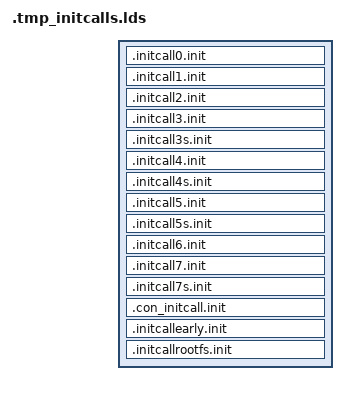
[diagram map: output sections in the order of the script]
SECTIONS {
	.initcall0.init : {
		*(.initcall0.init..kmod_core__443_830_bpf_jit_charge_init) ;
		*(.initcall0.init..kmod_memcontrol__764_1551_memory_stats_init) ;
		*(.initcall0.init..kmod_min_addr__299_53_init_mmap_min_addr) ;
		*(.initcall0.init..kmod_pci__471_6608_pci_realloc_setup_params) ;
		*(.initcall0.init..kmod_net_namespace__604_1140_net_ns_init) ;
	}
	.initcall1.init : {
		*(.initcall1.init..kmod_fpsimd__313_1449_fpsimd_init) ;
		*(.initcall1.init..kmod_process__417_747_tagged_addr_init) ;
		*(.initcall1.init..kmod_cpufeature__339_3096_enable_mrs_emulation) ;
		*(.initcall1.init..kmod_armv8_deprecated__334_647_armv8_deprecated_init) ;
		*(.initcall1.init..kmod_kaslr__313_198_kaslr_init) ;
		*(.initcall1.init..kmod_mmu__406_619_map_entry_trampoline) ;
		*(.initcall1.init..kmod_cpu__562_1806_alloc_frozen_cpus) ;
		*(.initcall1.init..kmod_cpu__564_1853_cpu_hotplug_pm_sync_init) ;
		*(.initcall1.init..kmod_workqueue__530_5652_wq_sysfs_init) ;
		*(.initcall1.init..kmod_ksysfs__308_269_ksysfs_init) ;
		*(.initcall1.init..kmod_cpufreq_schedutil__706_907_schedutil_gov_init) ;
		*(.initcall1.init..kmod_main__390_959_pm_init) ;
		*(.initcall1.init..kmod_update__437_238_rcu_set_runtime_mode) ;
		*(.initcall1.init..kmod_coherent__314_402_dma_init_reserved_memory) ;
		*(.initcall1.init..kmod_jiffies__297_86_init_jiffies_clocksource) ;
		*(.initcall1.init..kmod_futex__381_4044_futex_init) ;
		*(.initcall1.init..kmod_cgroup__737_5840_cgroup_wq_init) ;
		*(.initcall1.init..kmod_cgroup_v1__381_1253_cgroup1_wq_init) ;
		*(.initcall1.init..kmod_trace_events_synth__346_2079_trace_events_synth_init_early) ;
		*(.initcall1.init..kmod_trace_kprobe__365_1917_init_kprobe_trace_early) ;
		*(.initcall1.init..kmod_cpu_pm__272_213_cpu_pm_init) ;
		*(.initcall1.init..kmod_memcontrol__964_7530_mem_cgroup_swap_init) ;
		*(.initcall1.init..kmod_cma__437_161_cma_init_reserved_areas) ;
		*(.initcall1.init..kmod_fsnotify__331_572_fsnotify_init) ;
		*(.initcall1.init..kmod_locks__467_3023_filelock_init) ;
		*(.initcall1.init..kmod_binfmt_misc__342_832_init_misc_binfmt) ;
		*(.initcall1.init..kmod_binfmt_script__266_156_init_script_binfmt) ;
		*(.initcall1.init..kmod_binfmt_elf__346_2309_init_elf_binfmt) ;
		*(.initcall1.init..kmod_compat_binfmt_elf__346_2309_init_compat_elf_binfmt) ;
		*(.initcall1.init..kmod_configfs__329_179_configfs_init) ;
		*(.initcall1.init..kmod_debugfs__334_847_debugfs_init) ;
		*(.initcall1.init..kmod_tracefs__314_550_tracefs_init) ;
		*(.initcall1.init..kmod_inode__326_350_securityfs_init) ;
		*(.initcall1.init..kmod_random32__421_489_prandom_init_early) ;
		*(.initcall1.init..kmod_core__397_2305_pinctrl_init) ;
		*(.initcall1.init..kmod_gpiolib__447_4423_gpiolib_dev_init) ;
		*(.initcall1.init..kmod_crg_hi3516cv300__297_309_hi3516cv300_crg_init) ;
		*(.initcall1.init..kmod_clk_hi3519__297_194_hi3519_clk_init) ;
		*(.initcall1.init..kmod_clk_hi3660__261_637_hi3660_clk_init) ;
		*(.initcall1.init..kmod_clk_hi3670__261_1016_hi3670_clk_init) ;
		*(.initcall1.init..kmod_crg_hi3798cv200__297_392_hi3798cv200_crg_init) ;
		*(.initcall1.init..kmod_virtio__326_465_virtio_init) ;
		*(.initcall1.init..kmod_core__528_5860_regulator_init) ;
		*(.initcall1.init..kmod_iommu__427_2738_iommu_init) ;
		*(.initcall1.init..kmod_component__264_124_component_debug_init) ;
		*(.initcall1.init..kmod_domain__453_2956_genpd_bus_init) ;
		*(.initcall1.init..kmod_soc__237_192_soc_bus_register) ;
		*(.initcall1.init..kmod_arch_topology__346_296_register_cpufreq_notifier) ;
		*(.initcall1.init..kmod_debugfs__266_249_opp_debug_init) ;
		*(.initcall1.init..kmod_cpufreq__553_2887_cpufreq_core_init) ;
		*(.initcall1.init..kmod_cpufreq_performance__283_44_cpufreq_gov_performance_init) ;
		*(.initcall1.init..kmod_cpufreq_powersave__283_38_cpufreq_gov_powersave_init) ;
		*(.initcall1.init..kmod_cpufreq_conservative__287_340_CPU_FREQ_GOV_CONSERVATIVE_init) ;
		*(.initcall1.init..kmod_cpuidle__478_771_cpuidle_init) ;
		*(.initcall1.init..kmod_capsule__319_303_capsule_reboot_register) ;
		*(.initcall1.init..kmod_arm_runtime__316_178_arm_dmi_init) ;
		*(.initcall1.init..kmod_hi3660_mailbox__299_291_hi3660_mbox_init) ;
		*(.initcall1.init..kmod_hi6220_mailbox__308_366_hi6220_mbox_init) ;
		*(.initcall1.init..kmod_socket__666_3080_sock_init) ;
		*(.initcall1.init..kmod_sock__847_3388_net_inuse_init) ;
		*(.initcall1.init..kmod_net_namespace__573_393_net_defaults_init) ;
		*(.initcall1.init..kmod_flow_dissector__679_1808_init_default_flow_dissectors) ;
		*(.initcall1.init..kmod_af_netlink__671_2903_netlink_proto_init) ;
		*(.initcall1.init..kmod_genetlink__565_1411_genl_init) ;
	}
	.initcall2.init : {
		*(.initcall2.init..kmod_debug_monitors__318_139_debug_monitors_init) ;
		*(.initcall2.init..kmod_irqdesc__274_331_irq_sysfs_init) ;
		*(.initcall2.init..kmod_pool__316_225_dma_atomic_pool_init) ;
		*(.initcall2.init..kmod_audit__582_1690_audit_init) ;
		*(.initcall2.init..kmod_tracepoint__271_140_release_early_probes) ;
		*(.initcall2.init..kmod_backing_dev__474_231_bdi_class_init) ;
		*(.initcall2.init..kmod_mm_init__334_207_mm_sysfs_init) ;
		*(.initcall2.init..kmod_page_alloc__678_8141_init_per_zone_wmark_min) ;
		*(.initcall2.init..kmod_ramoops__318_975_ramoops_init) ;
		*(.initcall2.init..kmod_mpi__307_64_mpi_init) ;
		*(.initcall2.init..kmod_kobject_uevent__554_814_kobject_uevent_init) ;
		*(.initcall2.init..kmod_probe__320_108_pcibus_class_init) ;
		*(.initcall2.init..kmod_pci_driver__427_1659_pci_driver_init) ;
		*(.initcall2.init..kmod_backlight__343_770_backlight_class_init) ;
		*(.initcall2.init..kmod_bus__392_230_amba_init) ;
		*(.initcall2.init..kmod_hi6220_reset__303_221_hi6220_reset_init) ;
		*(.initcall2.init..kmod_tty_io__379_3515_tty_class_init) ;
		*(.initcall2.init..kmod_serdev__309_896_serdev_init) ;
		*(.initcall2.init..kmod_iommu_sysfs__304_47_iommu_dev_init) ;
		*(.initcall2.init..kmod_drm_mipi_dsi__362_1210_mipi_dsi_bus_init) ;
		*(.initcall2.init..kmod_core__430_603_devlink_class_init) ;
		*(.initcall2.init..kmod_swnode__276_973_software_node_init) ;
		*(.initcall2.init..kmod_wakeup__516_1238_wakeup_sources_debugfs_init) ;
		*(.initcall2.init..kmod_wakeup_stats__233_217_wakeup_sources_sysfs_init) ;
		*(.initcall2.init..kmod_regmap__439_3298_regmap_initcall) ;
		*(.initcall2.init..kmod_sram__268_429_sram_init) ;
		*(.initcall2.init..kmod_syscon__269_312_syscon_init) ;
		*(.initcall2.init..kmod_spi__521_4255_spi_init) ;
		*(.initcall2.init..kmod_spmi__368_591_spmi_init) ;
		*(.initcall2.init..kmod_i2c_core__404_1933_i2c_init) ;
		*(.initcall2.init..kmod_thermal_sys__487_1694_thermal_init) ;
		*(.initcall2.init..kmod_menu__262_574_init_menu) ;
		*(.initcall2.init..kmod_teo__260_494_teo_governor_init) ;
		*(.initcall2.init..kmod_rpmsg_core__301_635_rpmsg_init) ;
		*(.initcall2.init..kmod_rpmsg_char__345_572_rpmsg_char_init) ;
	}
	.initcall3.init : {
		*(.initcall3.init..kmod_setup__324_290_reserve_memblock_reserved_regions) ;
		*(.initcall3.init..kmod_vdso__318_381_aarch32_alloc_vdso_pages) ;
		*(.initcall3.init..kmod_vdso__320_486_vdso_init) ;
		*(.initcall3.init..kmod_hw_breakpoint__322_1018_arch_hw_breakpoint_init) ;
		*(.initcall3.init..kmod_context__324_399_asids_update_limit) ;
		*(.initcall3.init..kmod_kcmp__330_256_kcmp_cookies_init) ;
		*(.initcall3.init..kmod_cryptomgr__396_288_cryptomgr_init) ;
		*(.initcall3.init..kmod_dmaengine__321_293_dma_channel_table_init) ;
		*(.initcall3.init..kmod_dmaengine__393_1659_dma_bus_init) ;
		*(.initcall3.init..kmod_reset_hi3660__298_118_hi3660_reset_init) ;
		*(.initcall3.init..kmod_amba_pl011__414_2860_pl011_init) ;
		*(.initcall3.init..kmod_dma_iommu__357_1345_iommu_dma_init) ;
	}
	.initcall3s.init : {
		*(.initcall3s.init..kmod_platform__389_545_of_platform_default_populate_init) ;
	}
	.initcall4.init : {
		*(.initcall4.init..kmod_setup__326_421_topology_init) ;
		*(.initcall4.init..kmod_mte__388_486_register_mte_tcf_preferred_sysctl) ;
		*(.initcall4.init..kmod_user__245_235_uid_cache_init) ;
		*(.initcall4.init..kmod_params__366_958_param_sysfs_init) ;
		*(.initcall4.init..kmod_ucount__229_242_user_namespace_sysctl_init) ;
		*(.initcall4.init..kmod_stats__573_128_proc_schedstat_init) ;
		*(.initcall4.init..kmod_poweroff__165_45_pm_sysrq_init) ;
		*(.initcall4.init..kmod_profile__324_565_create_proc_profile) ;
		*(.initcall4.init..kmod_namespace__305_478_time_ns_init) ;
		*(.initcall4.init..kmod_cgroup__745_6662_cgroup_sysfs_init) ;
		*(.initcall4.init..kmod_namespace__320_157_cgroup_namespaces_init) ;
		*(.initcall4.init..kmod_hung_task__501_321_hung_task_init) ;
		*(.initcall4.init..kmod_bpf_trace__523_2183_send_signal_irq_work_init) ;
		*(.initcall4.init..kmod_devmap__518_876_dev_map_init) ;
		*(.initcall4.init..kmod_cpumap__505_768_cpu_map_init) ;
		*(.initcall4.init..kmod_net_namespace__436_566_netns_bpf_init) ;
		*(.initcall4.init..kmod_stackmap__436_874_stack_map_init) ;
		*(.initcall4.init..kmod_oom_kill__525_720_oom_init) ;
		*(.initcall4.init..kmod_backing_dev__476_248_default_bdi_init) ;
		*(.initcall4.init..kmod_backing_dev__504_692_cgwb_init) ;
		*(.initcall4.init..kmod_percpu__456_3183_percpu_enable_async) ;
		*(.initcall4.init..kmod_compaction__499_3005_kcompactd_init) ;
		*(.initcall4.init..kmod_mmap__561_3873_init_user_reserve) ;
		*(.initcall4.init..kmod_mmap__565_3894_init_admin_reserve) ;
		*(.initcall4.init..kmod_mmap__567_3964_init_reserve_notifier) ;
		*(.initcall4.init..kmod_swap_state__403_957_swap_init_sysfs) ;
		*(.initcall4.init..kmod_swapfile__477_3862_swapfile_init) ;
		*(.initcall4.init..kmod_huge_memory__397_446_hugepage_init) ;
		*(.initcall4.init..kmod_memcontrol__955_7174_mem_cgroup_init) ;
		*(.initcall4.init..kmod_cma_sysfs__268_118_cma_sysfs_init) ;
		*(.initcall4.init..kmod_io_wq__600_1242_io_wq_init) ;
		*(.initcall4.init..kmod_seqiv__329_183_seqiv_module_init) ;
		*(.initcall4.init..kmod_echainiv__329_160_echainiv_module_init) ;
		*(.initcall4.init..kmod_rsa_generic__314_281_rsa_init) ;
		*(.initcall4.init..kmod_cmac__277_311_crypto_cmac_module_init) ;
		*(.initcall4.init..kmod_hmac__325_254_hmac_module_init) ;
		*(.initcall4.init..kmod_xcbc__277_270_crypto_xcbc_module_init) ;
		*(.initcall4.init..kmod_crypto_null__331_221_crypto_null_mod_init) ;
		*(.initcall4.init..kmod_md5__278_245_md5_mod_init) ;
		*(.initcall4.init..kmod_sha1_generic__320_89_sha1_generic_mod_init) ;
		*(.initcall4.init..kmod_sha256_generic__321_113_sha256_generic_mod_init) ;
		*(.initcall4.init..kmod_sha512_generic__321_221_sha512_generic_mod_init) ;
		*(.initcall4.init..kmod_blake2b_generic__278_174_blake2b_mod_init) ;
		*(.initcall4.init..kmod_ecb__275_99_crypto_ecb_module_init) ;
		*(.initcall4.init..kmod_cbc__275_218_crypto_cbc_module_init) ;
		*(.initcall4.init..kmod_cts__323_405_crypto_cts_module_init) ;
		*(.initcall4.init..kmod_xts__323_462_xts_module_init) ;
		*(.initcall4.init..kmod_ctr__277_355_crypto_ctr_module_init) ;
		*(.initcall4.init..kmod_adiantum__340_613_adiantum_module_init) ;
		*(.initcall4.init..kmod_nhpoly1305__292_248_nhpoly1305_mod_init) ;
		*(.initcall4.init..kmod_gcm__341_1159_crypto_gcm_module_init) ;
		*(.initcall4.init..kmod_ccm__343_949_crypto_ccm_module_init) ;
		*(.initcall4.init..kmod_chacha20poly1305__341_671_chacha20poly1305_module_init) ;
		*(.initcall4.init..kmod_des_generic__273_125_des_generic_mod_init) ;
		*(.initcall4.init..kmod_aes_generic__270_1314_aes_init) ;
		*(.initcall4.init..kmod_chacha_generic__275_128_chacha_generic_mod_init) ;
		*(.initcall4.init..kmod_poly1305_generic__279_142_poly1305_mod_init) ;
		*(.initcall4.init..kmod_deflate__313_334_deflate_mod_init) ;
		*(.initcall4.init..kmod_crc32c_generic__277_161_crc32c_mod_init) ;
		*(.initcall4.init..kmod_crc32_generic__277_147_crc32_mod_init) ;
		*(.initcall4.init..kmod_authenc__420_464_crypto_authenc_module_init) ;
		*(.initcall4.init..kmod_authencesn__418_479_crypto_authenc_esn_module_init) ;
		*(.initcall4.init..kmod_lz4__269_155_lz4_mod_init) ;
		*(.initcall4.init..kmod_ansi_cprng__276_470_prng_mod_init) ;
		*(.initcall4.init..kmod_drbg__338_2146_drbg_init) ;
		*(.initcall4.init..kmod_ghash_generic__280_178_ghash_mod_init) ;
		*(.initcall4.init..kmod_zstd__313_253_zstd_mod_init) ;
		*(.initcall4.init..kmod_essiv__340_641_essiv_module_init) ;
		*(.initcall4.init..kmod_ecdh_generic__313_167_ecdh_init) ;
		*(.initcall4.init..kmod_bio__499_1686_init_bio) ;
		*(.initcall4.init..kmod_blk_settings__463_887_blk_settings_init) ;
		*(.initcall4.init..kmod_blk_ioc__367_422_blk_ioc_init) ;
		*(.initcall4.init..kmod_blk_mq__542_4036_blk_mq_init) ;
		*(.initcall4.init..kmod_genhd__400_1235_genhd_device_init) ;
		*(.initcall4.init..kmod_blk_cgroup__447_1943_blkcg_init) ;
		*(.initcall4.init..kmod_blk_crypto__352_79_bio_crypt_ctx_init) ;
		*(.initcall4.init..kmod_gpiolib__452_4550_gpiolib_debugfs_init) ;
		*(.initcall4.init..kmod_core__364_1347_pwm_debugfs_init) ;
		*(.initcall4.init..kmod_sysfs__233_554_pwm_sysfs_init) ;
		*(.initcall4.init..kmod_slot__329_379_pci_slot_init) ;
		*(.initcall4.init..kmod_clk_hi6220_stub__266_272_hi6220_stub_clk_init) ;
		*(.initcall4.init..kmod_clk_hi3660_stub__299_178_hi3660_stub_clk_init) ;
		*(.initcall4.init..kmod_fixed__377_290_regulator_fixed_voltage_init) ;
		*(.initcall4.init..kmod_misc__286_291_misc_init) ;
		*(.initcall4.init..kmod_iommu__335_152_iommu_subsys_init) ;
		*(.initcall4.init..kmod_arch_topology__341_115_register_cpu_capacity_sysctl) ;
		*(.initcall4.init..kmod_act8945a__302_82_act8945a_i2c_init) ;
		*(.initcall4.init..kmod_libnvdimm__399_616_libnvdimm_init) ;
		*(.initcall4.init..kmod_dax__386_763_dax_core_init) ;
		*(.initcall4.init..kmod_dma_buf__352_1551_dma_buf_init) ;
		*(.initcall4.init..kmod_dma_heap__348_463_dma_heap_init) ;
		*(.initcall4.init..kmod_scsi_mod__422_804_init_scsi) ;
		*(.initcall4.init..kmod_libphy__512_3061_phy_init) ;
		*(.initcall4.init..kmod_usb_common__398_412_usb_common_init) ;
		*(.initcall4.init..kmod_usbcore__424_1075_usb_init) ;
		*(.initcall4.init..kmod_udc_core__462_1772_usb_udc_init) ;
		*(.initcall4.init..kmod_typec__370_2132_typec_init) ;
		*(.initcall4.init..kmod_roles__285_387_usb_roles_init) ;
		*(.initcall4.init..kmod_serio__326_1052_serio_init) ;
		*(.initcall4.init..kmod_input_core__407_2528_input_init) ;
		*(.initcall4.init..kmod_rtc_core__274_478_rtc_init) ;
		*(.initcall4.init..kmod_i3c__330_2705_i3c_init) ;
		*(.initcall4.init..kmod_mc__312_323_media_devnode_init) ;
		*(.initcall4.init..kmod_videodev__335_1127_videodev_init) ;
		*(.initcall4.init..kmod_rc_core__337_2090_rc_core_init) ;
		*(.initcall4.init..kmod_cec__323_448_cec_devnode_init) ;
		*(.initcall4.init..kmod_power_supply__303_1458_power_supply_class_init) ;
		*(.initcall4.init..kmod_edac_core__314_163_edac_init) ;
		*(.initcall4.init..kmod_cpuidle_psci_domain__239_316_psci_idle_init_domains) ;
		*(.initcall4.init..kmod_mmc_core__434_2399_mmc_init) ;
		*(.initcall4.init..kmod_led_class__278_540_leds_init) ;
		*(.initcall4.init..kmod_scmi_module__426_1634_scmi_driver_init) ;
		*(.initcall4.init..kmod_efi__314_436_efisubsys_init) ;
		*(.initcall4.init..kmod_efi_init__313_367_register_gop_device) ;
		*(.initcall4.init..kmod_remoteproc__392_2479_remoteproc_init) ;
		*(.initcall4.init..kmod_devfreq__395_1882_devfreq_init) ;
		*(.initcall4.init..kmod_devfreq_event__251_482_devfreq_event_init) ;
		*(.initcall4.init..kmod_governor_simpleondemand__267_128_devfreq_simple_ondemand_init) ;
		*(.initcall4.init..kmod_governor_performance__267_48_devfreq_performance_init) ;
		*(.initcall4.init..kmod_governor_powersave__267_48_devfreq_powersave_init) ;
		*(.initcall4.init..kmod_governor_userspace__270_143_devfreq_userspace_init) ;
		*(.initcall4.init..kmod_governor_passive__268_192_devfreq_passive_init) ;
		*(.initcall4.init..kmod_industrialio__319_1882_iio_init) ;
		*(.initcall4.init..kmod_arm_pmu__344_1009_arm_pmu_hp_init) ;
		*(.initcall4.init..kmod_ras__351_38_ras_init) ;
		*(.initcall4.init..kmod_nvmem_core__318_1667_nvmem_init) ;
		*(.initcall4.init..kmod_soundcore__272_65_init_soundcore) ;
		*(.initcall4.init..kmod_snd__287_410_alsa_sound_init) ;
		*(.initcall4.init..kmod_sock__854_3688_proto_init) ;
		*(.initcall4.init..kmod_dev__1261_11336_net_dev_init) ;
		*(.initcall4.init..kmod_neighbour__693_3743_neigh_init) ;
		*(.initcall4.init..kmod_fib_notifier__404_199_fib_notifier_init) ;
		*(.initcall4.init..kmod_fib_rules__678_1298_fib_rules_init) ;
		*(.initcall4.init..kmod_netprio_cgroup__570_302_init_cgroup_netprio) ;
		*(.initcall4.init..kmod_sch_api__610_2304_pktsched_init) ;
		*(.initcall4.init..kmod_cls_api__734_3927_tc_filter_init) ;
		*(.initcall4.init..kmod_act_api__585_1690_tc_action_init) ;
		*(.initcall4.init..kmod_ethtool_nl__553_949_ethnl_init) ;
		*(.initcall4.init..kmod_nexthop__669_2025_nexthop_init) ;
		*(.initcall4.init..kmod_bluetooth__582_797_bt_init) ;
		*(.initcall4.init..kmod_wext_core__398_408_wireless_nlevent_init) ;
		*(.initcall4.init..kmod_rfkill__328_1370_rfkill_init) ;
		*(.initcall4.init..kmod_ieee802154__403_374_wpan_phy_class_init) ;
		*(.initcall4.init..kmod_mac802154__580_237_ieee802154_init) ;
		*(.initcall4.init..kmod_nfc__583_1227_nfc_init) ;
	}
	.initcall4s.init : {
		*(.initcall4s.init..kmod_cpufeature__337_2982_init_32bit_el0_mask) ;
		*(.initcall4s.init..kmod_watchdog__278_438_watchdog_init) ;
	}
	.initcall5.init : {
		*(.initcall5.init..kmod_debug_monitors__316_63_create_debug_debugfs_entry) ;
		*(.initcall5.init..kmod_energy_model__264_101_em_debug_init) ;
		*(.initcall5.init..kmod_clocksource__310_928_clocksource_done_booting) ;
		*(.initcall5.init..kmod_trace__444_9744_tracer_init_tracefs) ;
		*(.initcall5.init..kmod_trace_printk__338_382_init_trace_printk_function_export) ;
		*(.initcall5.init..kmod_trace_events_synth__348_2103_trace_events_synth_init) ;
		*(.initcall5.init..kmod_bpf_trace__528_2236_bpf_event_init) ;
		*(.initcall5.init..kmod_trace_kprobe__367_1947_init_kprobe_trace) ;
		*(.initcall5.init..kmod_trace_dynevent__338_225_init_dynamic_event) ;
		*(.initcall5.init..kmod_trace_uprobe__370_1659_init_uprobe_trace) ;
		*(.initcall5.init..kmod_inode__490_830_bpf_init) ;
		*(.initcall5.init..kmod_pipe__399_1447_init_pipe_fs) ;
		*(.initcall5.init..kmod_fs_writeback__543_1026_cgroup_writeback_init) ;
		*(.initcall5.init..kmod_inotify_user__410_842_inotify_user_setup) ;
		*(.initcall5.init..kmod_eventpoll__648_2439_eventpoll_init) ;
		*(.initcall5.init..kmod_anon_inodes__310_241_anon_inode_init) ;
		*(.initcall5.init..kmod_locks__465_3000_proc_locks_init) ;
		*(.initcall5.init..kmod_iomap__449_1578_iomap_init) ;
		*(.initcall5.init..kmod_dquot__419_2990_dquot_init) ;
		*(.initcall5.init..kmod_proc__258_19_proc_cmdline_init) ;
		*(.initcall5.init..kmod_proc__273_98_proc_consoles_init) ;
		*(.initcall5.init..kmod_proc__275_32_proc_cpuinfo_init) ;
		*(.initcall5.init..kmod_proc__349_60_proc_devices_init) ;
		*(.initcall5.init..kmod_proc__258_42_proc_interrupts_init) ;
		*(.initcall5.init..kmod_proc__301_33_proc_loadavg_init) ;
		*(.initcall5.init..kmod_proc__466_162_proc_meminfo_init) ;
		*(.initcall5.init..kmod_proc__296_239_proc_stat_init) ;
		*(.initcall5.init..kmod_proc__258_41_proc_uptime_init) ;
		*(.initcall5.init..kmod_proc__258_23_proc_version_init) ;
		*(.initcall5.init..kmod_proc__258_33_proc_softirqs_init) ;
		*(.initcall5.init..kmod_proc__288_66_proc_kmsg_init) ;
		*(.initcall5.init..kmod_proc__389_338_proc_page_init) ;
		*(.initcall5.init..kmod_proc__259_94_proc_boot_config_init) ;
		*(.initcall5.init..kmod_ramfs__362_285_init_ramfs_fs) ;
		*(.initcall5.init..kmod_scsi_ioctl__385_891_blk_scsi_ioctl_init) ;
		*(.initcall5.init..kmod_dynamic_debug__603_1160_dynamic_debug_init_control) ;
		*(.initcall5.init..kmod_mem__401_1100_chr_dev_init) ;
		*(.initcall5.init..kmod_firmware_class__399_1570_firmware_class_init) ;
		*(.initcall5.init..kmod_powercap_sys__297_674_powercap_init) ;
		*(.initcall5.init..kmod_sysctl_net_core__600_655_sysctl_core_init) ;
		*(.initcall5.init..kmod_eth__614_500_eth_offload_init) ;
		*(.initcall5.init..kmod_af_inet__719_1934_ipv4_offload_init) ;
		*(.initcall5.init..kmod_af_inet__722_2067_inet_init) ;
		*(.initcall5.init..kmod_unix__601_2985_af_unix_init) ;
		*(.initcall5.init..kmod_ip6_offload__619_445_ipv6_offload_init) ;
		*(.initcall5.init..kmod_xsk__621_1289_xsk_init) ;
	}
	.initcall5s.init : {
		*(.initcall5s.init..kmod_quirks__386_194_pci_apply_final_quirks) ;
	}
	.initcall6.init : {
		*(.initcall6.init..kmod_setup__328_455_register_arm64_panic_block) ;
		*(.initcall6.init..kmod_cpuinfo__267_324_cpuinfo_regs_init) ;
		*(.initcall6.init..kmod_cpufeature__333_1347_aarch32_el0_sysfs_init) ;
		*(.initcall6.init..kmod_perf_event__350_1256_armv8_pmu_driver_init) ;
		*(.initcall6.init..kmod_uprobes__315_208_arch_init_uprobes) ;
		*(.initcall6.init..kmod_mmu__447_1623_prevent_bootmem_remove_init) ;
		*(.initcall6.init..kmod_kvm__459_2159_arm_init) ;
		*(.initcall6.init..kmod_sha2_ce__286_182_cpu_feature_match_SHA2_init) ;
		*(.initcall6.init..kmod_aes_ce_cipher__273_178_cpu_feature_match_AES_init) ;
		*(.initcall6.init..kmod_aes_glue_ce__357_977_cpu_feature_match_AES_init) ;
		*(.initcall6.init..kmod_sha256_arm64__287_194_sha256_mod_init) ;
		*(.initcall6.init..kmod_chacha_neon__282_232_chacha_simd_mod_init) ;
		*(.initcall6.init..kmod_poly1305_neon__286_226_neon_poly1305_mod_init) ;
		*(.initcall6.init..kmod_exec_domain__326_35_proc_execdomains_init) ;
		*(.initcall6.init..kmod_panic__333_675_register_warn_debugfs) ;
		*(.initcall6.init..kmod_cpu__572_2753_cpuhp_sysfs_init) ;
		*(.initcall6.init..kmod_resource__308_146_ioresources_init) ;
		*(.initcall6.init..kmod_debug__584_888_init_sched_debug_procfs) ;
		*(.initcall6.init..kmod_psi__612_1408_psi_proc_init) ;
		*(.initcall6.init..kmod_generic_chip__283_649_irq_gc_init_ops) ;
		*(.initcall6.init..kmod_pm__381_249_irq_pm_init_ops) ;
		*(.initcall6.init..kmod_timekeeping__333_1889_timekeeping_init_ops) ;
		*(.initcall6.init..kmod_clocksource__326_1307_init_clocksource_sysfs) ;
		*(.initcall6.init..kmod_timer_list__308_387_init_timer_list_procfs) ;
		*(.initcall6.init..kmod_alarmtimer__356_988_alarmtimer_init) ;
		*(.initcall6.init..kmod_posix_timers__330_280_init_posix_timers) ;
		*(.initcall6.init..kmod_clockevents__320_777_clockevents_init_sysfs) ;
		*(.initcall6.init..kmod_sched_clock__268_300_sched_clock_syscore_init) ;
		*(.initcall6.init..kmod_module__435_4629_proc_modules_init) ;
		*(.initcall6.init..kmod_kallsyms__420_795_kallsyms_init) ;
		*(.initcall6.init..kmod_configs__266_75_ikconfig_init) ;
		*(.initcall6.init..kmod_kheaders__266_61_ikheaders_init) ;
		*(.initcall6.init..kmod_audit_watch__365_503_audit_watch_init) ;
		*(.initcall6.init..kmod_audit_fsnotify__349_192_audit_fsnotify_init) ;
		*(.initcall6.init..kmod_audit_tree__378_1089_audit_tree_init) ;
		*(.initcall6.init..kmod_seccomp__502_2338_seccomp_sysctl_init) ;
		*(.initcall6.init..kmod_utsname_sysctl__214_144_utsname_sysctl_init) ;
		*(.initcall6.init..kmod_tracepoint__296_759_init_tracepoints) ;
		*(.initcall6.init..kmod_core__722_13075_perf_event_sysfs_init) ;
		*(.initcall6.init..kmod_system_keyring__226_133_system_trusted_keyring_init) ;
		*(.initcall6.init..kmod_vmscan__543_4205_kswapd_init) ;
		*(.initcall6.init..kmod_vmstat__405_2193_extfrag_debug_init) ;
		*(.initcall6.init..kmod_mm_init__332_195_mm_compute_batch_init) ;
		*(.initcall6.init..kmod_slab_common__547_1087_slab_proc_init) ;
		*(.initcall6.init..kmod_workingset__384_629_workingset_init) ;
		*(.initcall6.init..kmod_vmalloc__521_3589_proc_vmalloc_init) ;
		*(.initcall6.init..kmod_memblock__362_2029_memblock_init_debugfs) ;
		*(.initcall6.init..kmod_swapfile__434_2870_procswaps_init) ;
		*(.initcall6.init..kmod_slub__587_5698_slab_sysfs_init) ;
		*(.initcall6.init..kmod_slub__595_5866_slab_debugfs_init) ;
		*(.initcall6.init..kmod_cleancache__315_315_init_cleancache) ;
		*(.initcall6.init..kmod_fcntl__352_1049_fcntl_init) ;
		*(.initcall6.init..kmod_filesystems__328_251_proc_filesystems_init) ;
		*(.initcall6.init..kmod_fs_writeback__568_2192_start_dirtytime_writeback) ;
		*(.initcall6.init..kmod_block_dev__398_522_blkdev_init) ;
		*(.initcall6.init..kmod_direct_io__355_1390_dio_init) ;
		*(.initcall6.init..kmod_userfaultfd__391_2118_userfaultfd_init) ;
		*(.initcall6.init..kmod_aio__366_280_aio_setup) ;
		*(.initcall6.init..kmod_io_uring__899_9920_io_uring_init) ;
		*(.initcall6.init..kmod_mbcache__287_432_mbcache_init) ;
		*(.initcall6.init..kmod_quota_v2__271_436_init_v2_quota_format) ;
		*(.initcall6.init..kmod_devpts__324_637_init_devpts_fs) ;
		*(.initcall6.init..kmod_ext4__1003_6739_ext4_init_fs) ;
		*(.initcall6.init..kmod_jbd2__500_3015_journal_init) ;
		*(.initcall6.init..kmod_fat__380_1978_init_fat_fs) ;
		*(.initcall6.init..kmod_vfat__328_1083_init_vfat_fs) ;
		*(.initcall6.init..kmod_msdos__326_686_init_msdos_fs) ;
		*(.initcall6.init..kmod_exfat__351_834_init_exfat_fs) ;
		*(.initcall6.init..kmod_nls_cp437__266_384_init_nls_cp437) ;
		*(.initcall6.init..kmod_nls_cp737__266_347_init_nls_cp737) ;
		*(.initcall6.init..kmod_nls_cp775__266_316_init_nls_cp775) ;
		*(.initcall6.init..kmod_nls_cp850__266_312_init_nls_cp850) ;
		*(.initcall6.init..kmod_nls_cp852__266_334_init_nls_cp852) ;
		*(.initcall6.init..kmod_nls_cp855__266_296_init_nls_cp855) ;
		*(.initcall6.init..kmod_nls_cp857__266_298_init_nls_cp857) ;
		*(.initcall6.init..kmod_nls_cp860__266_361_init_nls_cp860) ;
		*(.initcall6.init..kmod_nls_cp861__266_384_init_nls_cp861) ;
		*(.initcall6.init..kmod_nls_cp862__266_418_init_nls_cp862) ;
		*(.initcall6.init..kmod_nls_cp863__266_378_init_nls_cp863) ;
		*(.initcall6.init..kmod_nls_cp864__266_404_init_nls_cp864) ;
		*(.initcall6.init..kmod_nls_cp865__266_384_init_nls_cp865) ;
		*(.initcall6.init..kmod_nls_cp866__266_302_init_nls_cp866) ;
		*(.initcall6.init..kmod_nls_cp869__266_312_init_nls_cp869) ;
		*(.initcall6.init..kmod_nls_cp874__266_271_init_nls_cp874) ;
		*(.initcall6.init..kmod_nls_cp932__266_7929_init_nls_cp932) ;
		*(.initcall6.init..kmod_nls_euc_jp__266_577_init_nls_euc_jp) ;
		*(.initcall6.init..kmod_nls_cp936__266_11107_init_nls_cp936) ;
		*(.initcall6.init..kmod_nls_cp949__266_13942_init_nls_cp949) ;
		*(.initcall6.init..kmod_nls_cp950__266_9478_init_nls_cp950) ;
		*(.initcall6.init..kmod_nls_cp1250__266_343_init_nls_cp1250) ;
		*(.initcall6.init..kmod_nls_cp1251__266_298_init_nls_cp1251) ;
		*(.initcall6.init..kmod_nls_ascii__266_163_init_nls_ascii) ;
		*(.initcall6.init..kmod_nls_iso8859_1__266_254_init_nls_iso8859_1) ;
		*(.initcall6.init..kmod_nls_iso8859_2__266_305_init_nls_iso8859_2) ;
		*(.initcall6.init..kmod_nls_iso8859_3__266_305_init_nls_iso8859_3) ;
		*(.initcall6.init..kmod_nls_iso8859_4__266_305_init_nls_iso8859_4) ;
		*(.initcall6.init..kmod_nls_iso8859_5__266_269_init_nls_iso8859_5) ;
		*(.initcall6.init..kmod_nls_iso8859_6__266_260_init_nls_iso8859_6) ;
		*(.initcall6.init..kmod_nls_iso8859_7__266_314_init_nls_iso8859_7) ;
		*(.initcall6.init..kmod_nls_cp1255__266_380_init_nls_cp1255) ;
		*(.initcall6.init..kmod_nls_iso8859_9__266_269_init_nls_iso8859_9) ;
		*(.initcall6.init..kmod_nls_iso8859_13__266_282_init_nls_iso8859_13) ;
		*(.initcall6.init..kmod_nls_iso8859_14__266_338_init_nls_iso8859_14) ;
		*(.initcall6.init..kmod_nls_iso8859_15__266_304_init_nls_iso8859_15) ;
		*(.initcall6.init..kmod_nls_koi8_r__266_320_init_nls_koi8_r) ;
		*(.initcall6.init..kmod_nls_koi8_u__266_327_init_nls_koi8_u) ;
		*(.initcall6.init..kmod_nls_koi8_ru__266_79_init_nls_koi8_ru) ;
		*(.initcall6.init..kmod_nls_utf8__266_65_init_nls_utf8) ;
		*(.initcall6.init..kmod_mac_celtic__266_598_init_nls_macceltic) ;
		*(.initcall6.init..kmod_mac_centeuro__266_528_init_nls_maccenteuro) ;
		*(.initcall6.init..kmod_mac_croatian__266_598_init_nls_maccroatian) ;
		*(.initcall6.init..kmod_mac_cyrillic__266_493_init_nls_maccyrillic) ;
		*(.initcall6.init..kmod_mac_gaelic__266_563_init_nls_macgaelic) ;
		*(.initcall6.init..kmod_mac_greek__266_493_init_nls_macgreek) ;
		*(.initcall6.init..kmod_mac_iceland__266_598_init_nls_maciceland) ;
		*(.initcall6.init..kmod_mac_inuit__266_528_init_nls_macinuit) ;
		*(.initcall6.init..kmod_mac_romanian__266_598_init_nls_macromanian) ;
		*(.initcall6.init..kmod_mac_roman__266_633_init_nls_macroman) ;
		*(.initcall6.init..kmod_mac_turkish__266_598_init_nls_macturkish) ;
		*(.initcall6.init..kmod_fuse__406_1777_fuse_init) ;
		*(.initcall6.init..kmod_virtiofs__403_1529_virtio_fs_init) ;
		*(.initcall6.init..kmod_overlay__342_2128_ovl_init) ;
		*(.initcall6.init..kmod_incrementalfs__310_43_init_incfs_module) ;
		*(.initcall6.init..kmod_f2fs__685_4412_init_f2fs_fs) ;
		*(.initcall6.init..kmod_erofs__451_749_erofs_module_init) ;
		*(.initcall6.init..kmod_proc__301_58_key_proc_init) ;
		*(.initcall6.init..kmod_selinux__677_7404_selinux_nf_ip_init) ;
		*(.initcall6.init..kmod_selinux__603_2245_init_sel_fs) ;
		*(.initcall6.init..kmod_selinux__352_121_selnl_init) ;
		*(.initcall6.init..kmod_selinux__608_280_sel_netif_init) ;
		*(.initcall6.init..kmod_selinux__611_305_sel_netnode_init) ;
		*(.initcall6.init..kmod_selinux__611_239_sel_netport_init) ;
		*(.initcall6.init..kmod_selinux__646_3821_aurule_init) ;
		*(.initcall6.init..kmod_crypto_algapi__452_1293_crypto_algapi_init) ;
		*(.initcall6.init..kmod_jitterentropy_rng__270_217_jent_mod_init) ;
		*(.initcall6.init..kmod_asymmetric_keys__284_651_asymmetric_key_init) ;
		*(.initcall6.init..kmod_x509_key_parser__273_268_x509_key_init) ;
		*(.initcall6.init..kmod_genhd__424_1678_proc_genhd_init) ;
		*(.initcall6.init..kmod_bsg__369_530_bsg_init) ;
		*(.initcall6.init..kmod_blk_iocost__527_3428_ioc_init) ;
		*(.initcall6.init..kmod_mq_deadline__404_1167_deadline_init) ;
		*(.initcall6.init..kmod_kyber_iosched__426_1047_kyber_init) ;
		*(.initcall6.init..kmod_bfq__472_6864_bfq_init) ;
		*(.initcall6.init..kmod_libblake2s__280_88_mod_init) ;
		*(.initcall6.init..kmod_libchacha20poly1305__329_365_mod_init) ;
		*(.initcall6.init..kmod_libcurve25519__269_30_mod_init) ;
		*(.initcall6.init..kmod_libcrc32c__273_74_libcrc32c_mod_init) ;
		*(.initcall6.init..kmod_ts_kmp__269_152_init_kmp) ;
		*(.initcall6.init..kmod_ts_bm__271_202_init_bm) ;
		*(.initcall6.init..kmod_ts_fsm__269_336_init_fsm) ;
		*(.initcall6.init..kmod_percpu_counter__279_257_percpu_counter_startup) ;
		*(.initcall6.init..kmod_audit__305_85_audit_classes_init) ;
		*(.initcall6.init..kmod_sg_pool__309_190_sg_pool_init) ;
		*(.initcall6.init..kmod_irq_mbigen__303_388_mbigen_platform_driver_init) ;
		*(.initcall6.init..kmod_qcom_ebi2__298_403_qcom_ebi2_driver_init) ;
		*(.initcall6.init..kmod_phy_core__422_1168_phy_core_init) ;
		*(.initcall6.init..kmod_pinctrl_single__307_1991_pcs_driver_init) ;
		*(.initcall6.init..kmod_pinctrl_sun50i_a100__267_708_a100_pinctrl_driver_init) ;
		*(.initcall6.init..kmod_pinctrl_sun50i_a100_r__267_105_a100_r_pinctrl_driver_init) ;
		*(.initcall6.init..kmod_gpio_generic__302_816_bgpio_driver_init) ;
		*(.initcall6.init..kmod_gpio_pl061__380_424_pl061_gpio_driver_init) ;
		*(.initcall6.init..kmod_pcieportdrv__314_263_pcie_portdrv_init) ;
		*(.initcall6.init..kmod_proc__323_462_pci_proc_init) ;
		*(.initcall6.init..kmod_pci_epc_core__341_725_pci_epc_init) ;
		*(.initcall6.init..kmod_pci_epf_core__334_381_pci_epf_init) ;
		*(.initcall6.init..kmod_pci_host_generic__313_88_gen_pci_driver_init) ;
		*(.initcall6.init..kmod_pcie_designware_plat__315_267_dw_plat_pcie_driver_init) ;
		*(.initcall6.init..kmod_pcie_qcom__395_1502_qcom_pcie_driver_init) ;
		*(.initcall6.init..kmod_pcie_kirin__316_540_kirin_pcie_driver_init) ;
		*(.initcall6.init..kmod_clk_fixed_factor__277_259_of_fixed_factor_clk_driver_init) ;
		*(.initcall6.init..kmod_clk_fixed_rate__307_219_of_fixed_clk_driver_init) ;
		*(.initcall6.init..kmod_clk_gpio__240_249_gpio_clk_driver_init) ;
		*(.initcall6.init..kmod_clk_scpi__272_310_scpi_clocks_driver_init) ;
		*(.initcall6.init..kmod_sunxi_sram__300_401_sunxi_sram_driver_init) ;
		*(.initcall6.init..kmod_reset_scmi__270_128_scmi_reset_driver_init) ;
		*(.initcall6.init..kmod_reset_simple__263_202_reset_simple_driver_init) ;
		*(.initcall6.init..kmod_n_null__277_63_n_null_init) ;
		*(.initcall6.init..kmod_pty__325_968_pty_init) ;
		*(.initcall6.init..kmod_sysrq__407_1196_sysrq_init) ;
		*(.initcall6.init..kmod_hvc_dcc__318_280_hvc_dcc_init) ;
		*(.initcall6.init..kmod_8250__339_1246_serial8250_init) ;
		*(.initcall6.init..kmod_8250_pci__332_5753_serial_pci_driver_init) ;
		*(.initcall6.init..kmod_8250_of__325_336_of_platform_serial_driver_init) ;
		*(.initcall6.init..kmod_samsung_tty__341_2618_samsung_serial_driver_init) ;
		*(.initcall6.init..kmod_sprd_serial__343_1285_sprd_platform_driver_init) ;
		*(.initcall6.init..kmod_rng_core__287_647_hwrng_modinit) ;
		*(.initcall6.init..kmod_hisi_rng__302_117_hisi_rng_driver_init) ;
		*(.initcall6.init..kmod_cavium_rng__313_92_cavium_rng_pf_driver_init) ;
		*(.initcall6.init..kmod_cavium_rng_vf__314_91_cavium_rng_vf_driver_init) ;
		*(.initcall6.init..kmod_drm_kms_helper__330_88_drm_kms_helper_init) ;
		*(.initcall6.init..kmod_drm__341_1070_drm_core_init) ;
		*(.initcall6.init..kmod_ttm__267_98_ttm_init) ;
		*(.initcall6.init..kmod_topology__308_143_topology_sysfs_init) ;
		*(.initcall6.init..kmod_cacheinfo__235_674_cacheinfo_sysfs_init) ;
		*(.initcall6.init..kmod_devcoredump__313_341_devcoredump_init) ;
		*(.initcall6.init..kmod_brd__397_566_brd_init) ;
		*(.initcall6.init..kmod_loop__416_2430_loop_init) ;
		*(.initcall6.init..kmod_nd_pmem__386_655_nd_pmem_driver_init) ;
		*(.initcall6.init..kmod_nd_btt__402_1746_nd_btt_init) ;
		*(.initcall6.init..kmod_of_pmem__328_106_of_pmem_region_driver_init) ;
		*(.initcall6.init..kmod_deferred_free_helper__380_137_deferred_freelist_init) ;
		*(.initcall6.init..kmod_page_pool__385_246_dmabuf_page_pool_init_shrinker) ;
		*(.initcall6.init..kmod_ufshcd_core__564_9493_ufshcd_core_init) ;
		*(.initcall6.init..kmod_tc_dwc_g210_pltfrm__392_105_tc_dwc_g210_pltfm_driver_init) ;
		*(.initcall6.init..kmod_ufshcd_pci__395_402_ufshcd_pci_driver_init) ;
		*(.initcall6.init..kmod_ufs_hisi__393_603_ufs_hisi_pltform_init) ;
		*(.initcall6.init..kmod_sd_mod__440_3822_init_sd) ;
		*(.initcall6.init..kmod_dummy__392_209_dummy_init_module) ;
		*(.initcall6.init..kmod_wireguard__625_71_mod_init) ;
		*(.initcall6.init..kmod_ifb__411_355_ifb_init_module) ;
		*(.initcall6.init..kmod_Space__389_155_net_olddevs_init) ;
		*(.initcall6.init..kmod_loopback__561_277_blackhole_netdev_init) ;
		*(.initcall6.init..kmod_fixed_phy__400_369_fixed_mdio_bus_init) ;
		*(.initcall6.init..kmod_tun__789_3727_tun_init) ;
		*(.initcall6.init..kmod_veth__688_1474_veth_init) ;
		*(.initcall6.init..kmod_can_dev__579_1331_can_dev_init) ;
		*(.initcall6.init..kmod_ppp_generic__594_3411_ppp_init) ;
		*(.initcall6.init..kmod_bsd_comp__267_1167_bsdcomp_init) ;
		*(.initcall6.init..kmod_ppp_deflate__267_632_deflate_init) ;
		*(.initcall6.init..kmod_ppp_mppe__317_687_ppp_mppe_init) ;
		*(.initcall6.init..kmod_pppox__555_152_pppox_init) ;
		*(.initcall6.init..kmod_pptp__627_686_pptp_init_module) ;
		*(.initcall6.init..kmod_rtl8150__395_952_rtl8150_driver_init) ;
		*(.initcall6.init..kmod_r8152__630_6901_rtl8152_driver_init) ;
		*(.initcall6.init..kmod_cdc_ether__403_1002_cdc_driver_init) ;
		*(.initcall6.init..kmod_cdc_eem__397_362_eem_driver_init) ;
		*(.initcall6.init..kmod_usbnet__444_2167_usbnet_init) ;
		*(.initcall6.init..kmod_cdc_ncm__464_2031_cdc_ncm_driver_init) ;
		*(.initcall6.init..kmod_aqc111__399_1486_aq_driver_init) ;
		*(.initcall6.init..kmod_uio__319_1084_uio_init) ;
		*(.initcall6.init..kmod_dwc3__438_2046_dwc3_driver_init) ;
		*(.initcall6.init..kmod_dwc3_haps__317_142_dwc3_haps_driver_init) ;
		*(.initcall6.init..kmod_dwc3_of_simple__311_196_dwc3_of_simple_driver_init) ;
		*(.initcall6.init..kmod_dwc3_qcom__393_981_dwc3_qcom_driver_init) ;
		*(.initcall6.init..kmod_ehci_hcd__463_1383_ehci_hcd_init) ;
		*(.initcall6.init..kmod_ehci_pci__323_423_ehci_pci_init) ;
		*(.initcall6.init..kmod_ehci_platform__397_524_ehci_platform_init) ;
		*(.initcall6.init..kmod_xhci_hcd__540_5471_xhci_hcd_init) ;
		*(.initcall6.init..kmod_xhci_pci__497_670_xhci_pci_init) ;
		*(.initcall6.init..kmod_xhci_plat_hcd__392_568_xhci_plat_init) ;
		*(.initcall6.init..kmod_cdc_acm__295_2073_acm_init) ;
		*(.initcall6.init..kmod_uas__372_1281_uas_init) ;
		*(.initcall6.init..kmod_usb_storage__389_1159_usb_storage_driver_init) ;
		*(.initcall6.init..kmod_libcomposite__383_1941_gadget_cfs_init) ;
		*(.initcall6.init..kmod_dummy_hcd__357_2877_init) ;
		*(.initcall6.init..kmod_usb_f_acm__320_858_acmmod_init) ;
		*(.initcall6.init..kmod_u_serial__336_1495_userial_init) ;
		*(.initcall6.init..kmod_usb_f_serial__317_392_gsermod_init) ;
		*(.initcall6.init..kmod_usb_f_ncm__402_1746_ncmmod_init) ;
		*(.initcall6.init..kmod_usb_f_ecm__400_963_ecmmod_init) ;
		*(.initcall6.init..kmod_usb_f_eem__400_678_eemmod_init) ;
		*(.initcall6.init..kmod_usb_f_rndis__403_1030_rndismod_init) ;
		*(.initcall6.init..kmod_usb_f_mass_storage__397_3447_mass_storagemod_init) ;
		*(.initcall6.init..kmod_usb_f_fs__376_3846_ffsmod_init) ;
		*(.initcall6.init..kmod_usb_f_uac2__336_1463_uac2mod_init) ;
		*(.initcall6.init..kmod_usb_f_uvc__346_956_uvcmod_init) ;
		*(.initcall6.init..kmod_usb_f_midi__322_1428_midimod_init) ;
		*(.initcall6.init..kmod_usb_f_hid__338_1159_hidmod_init) ;
		*(.initcall6.init..kmod_usb_f_accessory__334_1541_accessorymod_init) ;
		*(.initcall6.init..kmod_usb_f_audio_source__323_1070_audio_sourcemod_init) ;
		*(.initcall6.init..kmod_tcpci__323_911_tcpci_i2c_driver_init) ;
		*(.initcall6.init..kmod_serport__287_308_serport_init) ;
		*(.initcall6.init..kmod_input_leds__271_209_input_leds_init) ;
		*(.initcall6.init..kmod_evdev__344_1441_evdev_init) ;
		*(.initcall6.init..kmod_atkbd__292_1913_atkbd_init) ;
		*(.initcall6.init..kmod_xpad__289_1969_xpad_driver_init) ;
		*(.initcall6.init..kmod_uinput__273_1095_uinput_misc_init) ;
		*(.initcall6.init..kmod_rtc_pl030__377_170_pl030_driver_init) ;
		*(.initcall6.init..kmod_rtc_pl031__377_470_pl031_driver_init) ;
		*(.initcall6.init..kmod_i2c_dev__286_775_i2c_dev_init) ;
		*(.initcall6.init..kmod_ir_kbd_i2c__316_949_ir_kbd_driver_init) ;
		*(.initcall6.init..kmod_uvcvideo__372_3050_uvc_init) ;
		*(.initcall6.init..kmod_gspca_main__361_1714_gspca_init) ;
		*(.initcall6.init..kmod_hisi_reboot__297_79_hisi_reboot_driver_init) ;
		*(.initcall6.init..kmod_hisi_thermal__309_671_hisi_thermal_driver_init) ;
		*(.initcall6.init..kmod_dm_mod__482_3179_dm_init) ;
		*(.initcall6.init..kmod_dm_bufio__418_2115_dm_bufio_init) ;
		*(.initcall6.init..kmod_dm_crypt__484_3596_dm_crypt_init) ;
		*(.initcall6.init..kmod_dm_default_key__355_419_dm_default_key_init) ;
		*(.initcall6.init..kmod_dm_snapshot__398_2871_dm_snapshot_init) ;
		*(.initcall6.init..kmod_dm_verity__368_1281_dm_verity_init) ;
		*(.initcall6.init..kmod_dm_bow__451_1296_dm_bow_init) ;
		*(.initcall6.init..kmod_dm_user__376_1289_dm_user_init) ;
		*(.initcall6.init..kmod_hci_uart__601_925_hci_uart_init) ;
		*(.initcall6.init..kmod_btsdio__587_374_btsdio_driver_init) ;
		*(.initcall6.init..kmod_scmi_cpufreq__280_277_scmi_cpufreq_drv_init) ;
		*(.initcall6.init..kmod_scpi_cpufreq__280_234_scpi_cpufreq_platdrv_init) ;
		*(.initcall6.init..kmod_cpuidle_arm__268_168_arm_idle_init) ;
		*(.initcall6.init..kmod_cpuidle_psci__278_414_psci_idle_init) ;
		*(.initcall6.init..kmod_mmc_block__401_3100_mmc_blk_init) ;
		*(.initcall6.init..kmod_sdhci__526_4857_sdhci_drv_init) ;
		*(.initcall6.init..kmod_sdhci_pltfm__359_258_sdhci_pltfm_drv_init) ;
		*(.initcall6.init..kmod_ledtrig_timer__268_136_timer_led_trigger_init) ;
		*(.initcall6.init..kmod_ledtrig_transient__269_194_transient_trigger_init) ;
		*(.initcall6.init..kmod_arm_scpi__387_1036_scpi_driver_init) ;
		*(.initcall6.init..kmod_esrt__309_432_esrt_sysfs_init) ;
		*(.initcall6.init..kmod_efi_pstore__276_462_efivars_pstore_init) ;
		*(.initcall6.init..kmod_soc_id__283_106_smccc_soc_init) ;
		*(.initcall6.init..kmod_hid__369_2628_hid_init) ;
		*(.initcall6.init..kmod_uhid__296_794_uhid_misc_init) ;
		*(.initcall6.init..kmod_hid_generic__270_82_hid_generic_init) ;
		*(.initcall6.init..kmod_hid_apple__277_635_apple_driver_init) ;
		*(.initcall6.init..kmod_hid_betopff__271_155_betop_driver_init) ;
		*(.initcall6.init..kmod_hid_elecom__273_98_elecom_driver_init) ;
		*(.initcall6.init..kmod_hid_logitech__276_955_lg_driver_init) ;
		*(.initcall6.init..kmod_hid_lg_g15__291_903_lg_g15_driver_init) ;
		*(.initcall6.init..kmod_hid_logitech_dj__323_1937_logi_djreceiver_driver_init) ;
		*(.initcall6.init..kmod_hid_logitech_hidpp__337_4086_hidpp_driver_init) ;
		*(.initcall6.init..kmod_hid_magicmouse__280_717_magicmouse_driver_init) ;
		*(.initcall6.init..kmod_hid_microsoft__271_467_ms_driver_init) ;
		*(.initcall6.init..kmod_hid_multitouch__302_2166_mt_driver_init) ;
		*(.initcall6.init..kmod_hid_nintendo__275_816_nintendo_hid_driver_init) ;
		*(.initcall6.init..kmod_hid_prodikeys__291_892_pk_driver_init) ;
		*(.initcall6.init..kmod_hid_picolcd__319_658_picolcd_driver_init) ;
		*(.initcall6.init..kmod_hid_plantronics__269_223_plantronics_driver_init) ;
		*(.initcall6.init..kmod_hid_playstation__279_1346_ps_init) ;
		*(.initcall6.init..kmod_hid_roccat__278_452_roccat_init) ;
		*(.initcall6.init..kmod_hid_roccat_arvo__284_450_arvo_init) ;
		*(.initcall6.init..kmod_hid_roccat_isku__281_452_isku_init) ;
		*(.initcall6.init..kmod_hid_roccat_kone__282_907_kone_init) ;
		*(.initcall6.init..kmod_hid_roccat_koneplus__284_566_koneplus_init) ;
		*(.initcall6.init..kmod_hid_roccat_konepure__278_224_konepure_init) ;
		*(.initcall6.init..kmod_hid_roccat_kovaplus__284_655_kovaplus_init) ;
		*(.initcall6.init..kmod_hid_roccat_lua__279_208_lua_driver_init) ;
		*(.initcall6.init..kmod_hid_roccat_pyra__285_602_pyra_init) ;
		*(.initcall6.init..kmod_hid_roccat_ryos__278_233_ryos_init) ;
		*(.initcall6.init..kmod_hid_roccat_savu__278_221_savu_init) ;
		*(.initcall6.init..kmod_hid_sony__294_3058_sony_init) ;
		*(.initcall6.init..kmod_hid_steam__290_1147_steam_controller_driver_init) ;
		*(.initcall6.init..kmod_hid_uclogic__276_420_uclogic_driver_init) ;
		*(.initcall6.init..kmod_wacom__348_2857_wacom_driver_init) ;
		*(.initcall6.init..kmod_hid_wiimote__278_1883_wiimote_hid_driver_init) ;
		*(.initcall6.init..kmod_usbhid__354_1693_hid_init) ;
		*(.initcall6.init..kmod_vhost_vsock__583_858_vhost_vsock_init) ;
		*(.initcall6.init..kmod_vhost__447_2636_vhost_init) ;
		*(.initcall6.init..kmod_ashmem__398_978_ashmem_init) ;
		*(.initcall6.init..kmod_debug_kinfo__311_195_debug_kinfo_driver_init) ;
		*(.initcall6.init..kmod_sun6i_msgbox__301_322_sun6i_msgbox_driver_init) ;
		*(.initcall6.init..kmod_extcon_core__294_1416_extcon_class_init) ;
		*(.initcall6.init..kmod_binder__607_6196_binder_init) ;
		*(.initcall6.init..kmod_debug_symbols__381_123_debug_symbol_init) ;
		*(.initcall6.init..kmod_gnss__317_409_gnss_module_init) ;
		*(.initcall6.init..kmod_icc_core__395_1140_icc_init) ;
		*(.initcall6.init..kmod_snd_hwdep__292_542_alsa_hwdep_init) ;
		*(.initcall6.init..kmod_snd_timer__348_2347_alsa_timer_init) ;
		*(.initcall6.init..kmod_snd_hrtimer__274_168_snd_hrtimer_init) ;
		*(.initcall6.init..kmod_snd_pcm__338_1235_alsa_pcm_init) ;
		*(.initcall6.init..kmod_snd_rawmidi__376_1949_alsa_rawmidi_init) ;
		*(.initcall6.init..kmod_snd_usb_audio__369_1297_usb_audio_driver_init) ;
		*(.initcall6.init..kmod_snd_soc_core__509_3218_snd_soc_init) ;
		*(.initcall6.init..kmod_sock_diag__572_339_sock_diag_init) ;
		*(.initcall6.init..kmod_llc__396_156_llc_init) ;
		*(.initcall6.init..kmod_psnap__399_109_snap_init) ;
		*(.initcall6.init..kmod_sch_blackhole__409_41_blackhole_init) ;
		*(.initcall6.init..kmod_act_police__426_410_police_init_module) ;
		*(.initcall6.init..kmod_act_gact__421_308_gact_init_module) ;
		*(.initcall6.init..kmod_act_mirred__428_498_mirred_init_module) ;
		*(.initcall6.init..kmod_act_skbedit__602_378_skbedit_init_module) ;
		*(.initcall6.init..kmod_act_bpf__557_452_bpf_init_module) ;
		*(.initcall6.init..kmod_sch_htb__448_1597_htb_module_init) ;
		*(.initcall6.init..kmod_sch_ingress__412_303_ingress_module_init) ;
		*(.initcall6.init..kmod_sch_sfq__584_938_sfq_module_init) ;
		*(.initcall6.init..kmod_sch_tbf__426_609_tbf_module_init) ;
		*(.initcall6.init..kmod_sch_prio__413_441_prio_module_init) ;
		*(.initcall6.init..kmod_sch_multiq__413_418_multiq_module_init) ;
		*(.initcall6.init..kmod_sch_netem__579_1299_netem_module_init) ;
		*(.initcall6.init..kmod_sch_codel__561_304_codel_module_init) ;
		*(.initcall6.init..kmod_sch_fq_codel__573_720_fq_codel_module_init) ;
		*(.initcall6.init..kmod_sch_fq__639_1074_fq_module_init) ;
		*(.initcall6.init..kmod_cls_u32__453_1427_init_u32) ;
		*(.initcall6.init..kmod_cls_fw__428_459_init_fw) ;
		*(.initcall6.init..kmod_cls_basic__428_352_init_basic) ;
		*(.initcall6.init..kmod_cls_flow__649_720_cls_flow_init) ;
		*(.initcall6.init..kmod_cls_bpf__576_722_cls_bpf_init_mod) ;
		*(.initcall6.init..kmod_cls_matchall__416_438_cls_mall_init) ;
		*(.initcall6.init..kmod_em_cmp__414_92_init_em_cmp) ;
		*(.initcall6.init..kmod_em_nbyte__414_73_init_em_nbyte) ;
		*(.initcall6.init..kmod_em_u32__414_57_init_em_u32) ;
		*(.initcall6.init..kmod_em_meta__584_1008_init_em_meta) ;
		*(.initcall6.init..kmod_em_text__414_150_init_em_text) ;
		*(.initcall6.init..kmod_nfnetlink__578_675_nfnetlink_init) ;
		*(.initcall6.init..kmod_nfnetlink_queue__699_1581_nfnetlink_queue_init) ;
		*(.initcall6.init..kmod_nfnetlink_log__594_1202_nfnetlink_log_init) ;
		*(.initcall6.init..kmod_nf_conntrack__629_1208_nf_conntrack_standalone_init) ;
		*(.initcall6.init..kmod_nf_conntrack_netlink__647_3947_ctnetlink_init) ;
		*(.initcall6.init..kmod_nf_conntrack_amanda__638_239_nf_conntrack_amanda_init) ;
		*(.initcall6.init..kmod_nf_conntrack_ftp__674_610_nf_conntrack_ftp_init) ;
		*(.initcall6.init..kmod_nf_conntrack_h323__684_1836_nf_conntrack_h323_init) ;
		*(.initcall6.init..kmod_nf_conntrack_irc__634_281_nf_conntrack_irc_init) ;
		*(.initcall6.init..kmod_nf_conntrack_netbios_ns__629_69_nf_conntrack_netbios_ns_init) ;
		*(.initcall6.init..kmod_nf_conntrack_pptp__638_634_nf_conntrack_pptp_init) ;
		*(.initcall6.init..kmod_nf_conntrack_sane__627_217_nf_conntrack_sane_init) ;
		*(.initcall6.init..kmod_nf_conntrack_tftp__634_140_nf_conntrack_tftp_init) ;
		*(.initcall6.init..kmod_nf_nat__649_1206_nf_nat_init) ;
		*(.initcall6.init..kmod_nf_nat_amanda__627_91_nf_nat_amanda_init) ;
		*(.initcall6.init..kmod_nf_nat_ftp__627_150_nf_nat_ftp_init) ;
		*(.initcall6.init..kmod_nf_nat_irc__627_121_nf_nat_irc_init) ;
		*(.initcall6.init..kmod_nf_nat_tftp__627_55_nf_nat_tftp_init) ;
		*(.initcall6.init..kmod_nf_conncount__649_620_nf_conncount_modinit) ;
		*(.initcall6.init..kmod_x_tables__702_1915_xt_init) ;
		*(.initcall6.init..kmod_xt_tcpudp__632_231_tcpudp_mt_init) ;
		*(.initcall6.init..kmod_xt_mark__401_81_mark_mt_init) ;
		*(.initcall6.init..kmod_xt_connmark__631_205_connmark_mt_init) ;
		*(.initcall6.init..kmod_xt_nat__620_238_xt_nat_init) ;
		*(.initcall6.init..kmod_xt_CLASSIFY__629_69_classify_tg_init) ;
		*(.initcall6.init..kmod_xt_CONNSECMARK__629_138_connsecmark_tg_init) ;
		*(.initcall6.init..kmod_xt_CT__662_397_xt_ct_tg_init) ;
		*(.initcall6.init..kmod_xt_DSCP__574_160_dscp_tg_init) ;
		*(.initcall6.init..kmod_xt_NETMAP__659_162_netmap_tg_init) ;
		*(.initcall6.init..kmod_xt_NFLOG__398_80_nflog_tg_init) ;
		*(.initcall6.init..kmod_xt_NFQUEUE__573_157_nfqueue_tg_init) ;
		*(.initcall6.init..kmod_xt_REDIRECT__661_111_redirect_tg_init) ;
		*(.initcall6.init..kmod_xt_MASQUERADE__624_123_masquerade_tg_init) ;
		*(.initcall6.init..kmod_xt_SECMARK__398_190_secmark_tg_init) ;
		*(.initcall6.init..kmod_xt_TPROXY__625_271_tproxy_tg_init) ;
		*(.initcall6.init..kmod_xt_TCPMSS__634_344_tcpmss_tg_init) ;
		*(.initcall6.init..kmod_xt_TEE__583_224_tee_tg_init) ;
		*(.initcall6.init..kmod_xt_TRACE__397_53_trace_tg_init) ;
		*(.initcall6.init..kmod_xt_IDLETIMER__564_786_idletimer_tg_init) ;
		*(.initcall6.init..kmod_xt_bpf__435_152_bpf_mt_init) ;
		*(.initcall6.init..kmod_xt_comment__398_45_comment_mt_init) ;
		*(.initcall6.init..kmod_xt_connlimit__623_131_connlimit_mt_init) ;
		*(.initcall6.init..kmod_xt_conntrack__627_326_conntrack_mt_init) ;
		*(.initcall6.init..kmod_xt_dscp__574_109_dscp_mt_init) ;
		*(.initcall6.init..kmod_xt_ecn__628_175_ecn_mt_init) ;
		*(.initcall6.init..kmod_xt_esp__628_103_esp_mt_init) ;
		*(.initcall6.init..kmod_xt_hashlimit__648_1331_hashlimit_mt_init) ;
		*(.initcall6.init..kmod_xt_helper__630_95_helper_mt_init) ;
		*(.initcall6.init..kmod_xt_hl__572_92_hl_mt_init) ;
		*(.initcall6.init..kmod_xt_iprange__566_130_iprange_mt_init) ;
		*(.initcall6.init..kmod_xt_l2tp__629_354_l2tp_mt_init) ;
		*(.initcall6.init..kmod_xt_length__594_66_length_mt_init) ;
		*(.initcall6.init..kmod_xt_limit__398_208_limit_mt_init) ;
		*(.initcall6.init..kmod_xt_mac__628_62_mac_mt_init) ;
		*(.initcall6.init..kmod_xt_multiport__628_175_multiport_mt_init) ;
		*(.initcall6.init..kmod_xt_owner__559_144_owner_mt_init) ;
		*(.initcall6.init..kmod_xt_pkttype__572_60_pkttype_mt_init) ;
		*(.initcall6.init..kmod_xt_policy__598_186_policy_mt_init) ;
		*(.initcall6.init..kmod_xt_quota__398_91_quota_mt_init) ;
		*(.initcall6.init..kmod_xt_quota2__399_390_quota_mt2_init) ;
		*(.initcall6.init..kmod_xt_socket__623_313_socket_mt_init) ;
		*(.initcall6.init..kmod_xt_state__626_74_state_mt_init) ;
		*(.initcall6.init..kmod_xt_statistic__398_98_statistic_mt_init) ;
		*(.initcall6.init..kmod_xt_string__399_92_string_mt_init) ;
		*(.initcall6.init..kmod_xt_time__392_294_time_mt_init) ;
		*(.initcall6.init..kmod_xt_u32__392_118_u32_mt_init) ;
		*(.initcall6.init..kmod_gre_offload__614_290_gre_offload_init) ;
		*(.initcall6.init..kmod_sysctl_net_ipv4__624_1451_sysctl_ipv4_init) ;
		*(.initcall6.init..kmod_ipip__630_712_ipip_init) ;
		*(.initcall6.init..kmod_gre__627_217_gre_init) ;
		*(.initcall6.init..kmod_ip_gre__635_1774_ipgre_init) ;
		*(.initcall6.init..kmod_ip_vti__628_719_vti_init) ;
		*(.initcall6.init..kmod_esp4__636_1240_esp4_init) ;
		*(.initcall6.init..kmod_tunnel4__599_298_tunnel4_init) ;
		*(.initcall6.init..kmod_nf_defrag_ipv4__629_154_nf_defrag_init) ;
		*(.initcall6.init..kmod_nf_nat_h323__676_627_init) ;
		*(.initcall6.init..kmod_nf_nat_pptp__633_323_nf_nat_helper_pptp_init) ;
		*(.initcall6.init..kmod_ip_tables__603_1931_ip_tables_init) ;
		*(.initcall6.init..kmod_iptable_filter__593_117_iptable_filter_init) ;
		*(.initcall6.init..kmod_iptable_mangle__592_154_iptable_mangle_init) ;
		*(.initcall6.init..kmod_iptable_nat__628_153_iptable_nat_init) ;
		*(.initcall6.init..kmod_iptable_raw__590_126_iptable_raw_init) ;
		*(.initcall6.init..kmod_iptable_security__592_114_iptable_security_init) ;
		*(.initcall6.init..kmod_ipt_REJECT__592_109_reject_tg_init) ;
		*(.initcall6.init..kmod_arp_tables__569_1641_arp_tables_init) ;
		*(.initcall6.init..kmod_arpt_mangle__560_91_arpt_mangle_init) ;
		*(.initcall6.init..kmod_arptable_filter__396_108_arptable_filter_init) ;
		*(.initcall6.init..kmod_inet_diag__635_1477_inet_diag_init) ;
		*(.initcall6.init..kmod_tcp_diag__618_235_tcp_diag_init) ;
		*(.initcall6.init..kmod_udp_diag__584_298_udp_diag_init) ;
		*(.initcall6.init..kmod_tcp_cubic__641_534_cubictcp_register) ;
		*(.initcall6.init..kmod_xfrm_user__601_3472_xfrm_user_init) ;
		*(.initcall6.init..kmod_xfrm_interface__669_1019_xfrmi_init) ;
		*(.initcall6.init..kmod_ipv6__697_1282_inet6_init) ;
		*(.initcall6.init..kmod_esp6__668_1287_esp6_init) ;
		*(.initcall6.init..kmod_ipcomp6__619_214_ipcomp6_init) ;
		*(.initcall6.init..kmod_xfrm6_tunnel__599_399_xfrm6_tunnel_init) ;
		*(.initcall6.init..kmod_tunnel6__605_303_tunnel6_init) ;
		*(.initcall6.init..kmod_mip6__588_506_mip6_init) ;
		*(.initcall6.init..kmod_ip6_tables__637_1943_ip6_tables_init) ;
		*(.initcall6.init..kmod_ip6table_filter__627_118_ip6table_filter_init) ;
		*(.initcall6.init..kmod_ip6table_mangle__626_145_ip6table_mangle_init) ;
		*(.initcall6.init..kmod_ip6table_raw__624_125_ip6table_raw_init) ;
		*(.initcall6.init..kmod_nf_defrag_ipv6__664_155_nf_defrag_init) ;
		*(.initcall6.init..kmod_ip6t_rpfilter__620_149_rpfilter_mt_init) ;
		*(.initcall6.init..kmod_ip6t_REJECT__626_120_reject_tg6_init) ;
		*(.initcall6.init..kmod_ip6_vti__685_1323_vti6_tunnel_init) ;
		*(.initcall6.init..kmod_sit__661_2012_sit_init) ;
		*(.initcall6.init..kmod_ip6_tunnel__714_2426_ip6_tunnel_init) ;
		*(.initcall6.init..kmod_ip6_gre__667_2390_ip6gre_init) ;
		*(.initcall6.init..kmod_af_packet__664_4703_packet_init) ;
		*(.initcall6.init..kmod_af_key__598_3912_ipsec_pfkey_init) ;
		*(.initcall6.init..kmod_bridge__617_402_br_init) ;
		*(.initcall6.init..kmod_can__599_918_can_init) ;
		*(.initcall6.init..kmod_can_raw__563_952_raw_module_init) ;
		*(.initcall6.init..kmod_can_bcm__585_1758_bcm_module_init) ;
		*(.initcall6.init..kmod_can_gw__572_1259_cgw_module_init) ;
		*(.initcall6.init..kmod_rfcomm__622_2229_rfcomm_init) ;
		*(.initcall6.init..kmod_hidp__600_1472_hidp_init) ;
		*(.initcall6.init..kmod_l2tp_core__740_1711_l2tp_init) ;
		*(.initcall6.init..kmod_l2tp_ppp__610_1727_pppol2tp_init) ;
		*(.initcall6.init..kmod_tipc__583_227_tipc_init) ;
		*(.initcall6.init..kmod_diag__583_112_tipc_diag_init) ;
		*(.initcall6.init..kmod_6lowpan__576_178_lowpan_module_init) ;
		*(.initcall6.init..kmod_nhc_dest__569_22_nhc_dest_init) ;
		*(.initcall6.init..kmod_nhc_fragment__569_21_nhc_fragment_init) ;
		*(.initcall6.init..kmod_nhc_hop__569_21_nhc_hop_init) ;
		*(.initcall6.init..kmod_nhc_ipv6__569_21_nhc_ipv6_init) ;
		*(.initcall6.init..kmod_nhc_mobility__569_21_nhc_mobility_init) ;
		*(.initcall6.init..kmod_nhc_routing__569_21_nhc_routing_init) ;
		*(.initcall6.init..kmod_nhc_udp__569_181_nhc_udp_init) ;
		*(.initcall6.init..kmod_ieee802154_socket__599_1130_af_ieee802154_init) ;
		*(.initcall6.init..kmod_ieee802154_6lowpan__570_280_lowpan_init_module) ;
		*(.initcall6.init..kmod_vsock__583_2243_vsock_init) ;
		*(.initcall6.init..kmod_vsock_diag__553_174_vsock_diag_init) ;
		*(.initcall6.init..kmod_vsock_loopback__563_175_vsock_loopback_init) ;
	}
	.initcall7.init : {
		*(.initcall7.init..kmod_panic__330_552_init_oops_id) ;
		*(.initcall7.init..kmod_debug__574_184_sched_init_debug) ;
		*(.initcall7.init..kmod_qos__427_427_cpu_latency_qos_init) ;
		*(.initcall7.init..kmod_main__387_460_pm_debugfs_init) ;
		*(.initcall7.init..kmod_wakeup_reason__391_438_wakeup_reason_init) ;
		*(.initcall7.init..kmod_printk__391_3186_printk_late_init) ;
		*(.initcall7.init..kmod_srcutree__399_1449_init_srcu_module_notifier) ;
		*(.initcall7.init..kmod_swiotlb__346_753_swiotlb_create_debugfs) ;
		*(.initcall7.init..kmod_timekeeping_debug__377_44_tk_debug_sleep_time_init) ;
		*(.initcall7.init..kmod_kprobes__418_2960_debugfs_kprobe_init) ;
		*(.initcall7.init..kmod_taskstats__366_698_taskstats_init) ;
		*(.initcall7.init..kmod_map_iter__416_195_bpf_map_iter_init) ;
		*(.initcall7.init..kmod_task_iter__423_361_task_iter_init) ;
		*(.initcall7.init..kmod_prog_iter__416_107_bpf_prog_iter_init) ;
		*(.initcall7.init..kmod_trampoline__446_574_init_trampolines) ;
		*(.initcall7.init..kmod_system_keyring__228_145_load_system_certificate_list) ;
		*(.initcall7.init..kmod_memory__574_4229_fault_around_debugfs) ;
		*(.initcall7.init..kmod_swapfile__437_2879_max_swapfiles_check) ;
		*(.initcall7.init..kmod_core__393_588_kfence_debugfs_init) ;
		*(.initcall7.init..kmod_huge_memory__408_2948_split_huge_pages_debugfs) ;
		*(.initcall7.init..kmod_page_owner__346_687_pageowner_init) ;
		*(.initcall7.init..kmod_page_pinner__338_514_page_pinner_init) ;
		*(.initcall7.init..kmod_early_ioremap__307_103_check_early_ioremap_leak) ;
		*(.initcall7.init..kmod_cma_debug__266_200_cma_debugfs_init) ;
		*(.initcall7.init..kmod_usercopy__315_309_set_hardened_usercopy) ;
		*(.initcall7.init..kmod_fscrypto__371_404_fscrypt_init) ;
		*(.initcall7.init..kmod_init__259_61_fsverity_init) ;
		*(.initcall7.init..kmod_pstore__278_838_pstore_init) ;
		*(.initcall7.init..kmod_process_keys__350_956_init_root_keyring) ;
		*(.initcall7.init..kmod_integrity__307_230_integrity_fs_init) ;
		*(.initcall7.init..kmod_blk_timeout__356_99_blk_timeout_init) ;
		*(.initcall7.init..kmod_random32__427_632_prandom_init_late) ;
		*(.initcall7.init..kmod_error_inject__319_242_init_error_injection) ;
		*(.initcall7.init..kmod_pci__468_6433_pci_resource_alignment_sysfs_init) ;
		*(.initcall7.init..kmod_pci_sysfs__350_1454_pci_sysfs_init) ;
		*(.initcall7.init..kmod_bus__404_531_amba_deferred_retry) ;
		*(.initcall7.init..kmod_clk__511_3416_clk_debug_init) ;
		*(.initcall7.init..kmod_core__456_1133_sync_state_resume_initcall) ;
		*(.initcall7.init..kmod_dd__318_340_deferred_probe_initcall) ;
		*(.initcall7.init..kmod_domain__403_1005_genpd_power_off_unused) ;
		*(.initcall7.init..kmod_domain__467_3280_genpd_debug_init) ;
		*(.initcall7.init..kmod_gpio_keys__311_1030_gpio_keys_init) ;
		*(.initcall7.init..kmod_reboot__263_77_efi_shutdown_init) ;
		*(.initcall7.init..kmod_earlycon__305_50_efi_earlycon_unmap_fb) ;
		*(.initcall7.init..kmod_fdt__319_1321_of_fdt_raw_init) ;
		*(.initcall7.init..kmod_dtpm__243_483_dtpm_init) ;
		*(.initcall7.init..kmod_bpf_sk_storage__586_872_bpf_sk_storage_map_iter_init) ;
		*(.initcall7.init..kmod_tcp_cong__624_256_tcp_congestion_default) ;
		*(.initcall7.init..kmod_udp_tunnel__630_959_udp_tunnel_nic_init_module) ;
	}
	.initcall7s.init : {
		*(.initcall7s.init..kmod_topology__247_263_init_amu_fie) ;
		*(.initcall7s.init..kmod_trace__446_9745_clear_boot_tracer) ;
		*(.initcall7s.init..kmod_clk__454_1309_clk_disable_unused) ;
		*(.initcall7s.init..kmod_core__530_5963_regulator_init_complete) ;
		*(.initcall7s.init..kmod_platform__391_552_of_platform_sync_state_init) ;
		*(.initcall7s.init..kmod_last__231_29_alsa_sound_last_init) ;
	}
	.con_initcall.init : {
		*(.con_initcall.init..kmod_hvc_dcc__316_267_hvc_dcc_console_init) ;
		*(.con_initcall.init..kmod_hvc_console__276_246_hvc_console_init) ;
		*(.con_initcall.init..kmod_8250__332_693_univ8250_console_init) ;
		*(.con_initcall.init..kmod_samsung_tty__337_1598_s3c24xx_serial_console_init) ;
		*(.con_initcall.init..kmod_sprd_serial__340_1056_sprd_serial_console_init) ;
	}
	.initcallearly.init : {
		*(.initcallearly.init..kmod_ptrace__393_42_trace_init_flags_sys_enter) ;
		*(.initcallearly.init..kmod_ptrace__395_66_trace_init_flags_sys_exit) ;
		*(.initcallearly.init..kmod_suspend__316_152_cpu_suspend_init) ;
		*(.initcallearly.init..kmod_context__326_424_asids_init) ;
		*(.initcallearly.init..kmod_softirq__379_752_spawn_ksoftirqd) ;
		*(.initcallearly.init..kmod_core__891_7396_migration_init) ;
		*(.initcallearly.init..kmod_srcutree__396_1372_srcu_bootup_announce) ;
		*(.initcallearly.init..kmod_tree__626_4282_rcu_spawn_gp_kthread) ;
		*(.initcallearly.init..kmod_tree__634_106_check_cpu_stall_init) ;
		*(.initcallearly.init..kmod_tree__689_866_rcu_sysrq_init) ;
		*(.initcallearly.init..kmod_stop_machine__312_604_cpu_stop_init) ;
		*(.initcallearly.init..kmod_kprobes__401_2650_init_kprobes) ;
		*(.initcallearly.init..kmod_trace_output__347_1399_init_events) ;
		*(.initcallearly.init..kmod_trace_printk__340_389_init_trace_printk) ;
		*(.initcallearly.init..kmod_trace_events__544_3456_event_trace_enable_again) ;
		*(.initcallearly.init..kmod_jump_label__282_772_jump_label_init_module) ;
		*(.initcallearly.init..kmod_memory__546_173_init_zero_pfn) ;
		*(.initcallearly.init..kmod_dynamic_debug__601_1157_dynamic_debug_init) ;
		*(.initcallearly.init..kmod_vsprintf__576_791_initialize_ptr_random) ;
		*(.initcallearly.init..kmod_irq_gic_v3_its_platform_msi__269_163_its_pmsi_init) ;
		*(.initcallearly.init..kmod_irq_gic_v3_its_pci_msi__323_198_its_pci_msi_init) ;
		*(.initcallearly.init..kmod_uid_sys_stats__324_706_proc_uid_sys_stats_init) ;
		*(.initcallearly.init..kmod_efi__317_993_efi_memreserve_root_init) ;
		*(.initcallearly.init..kmod_arm_runtime__314_153_arm_enable_runtime_services) ;
		*(.initcallearly.init..kmod_earlycon__303_41_efi_earlycon_remap_fb) ;
		*(.initcallearly.init..kmod_dummy_timer__261_37_dummy_timer_register) ;
	}
	.initcallrootfs.init : {
		*(.initcallrootfs.init..kmod_initramfs__331_642_populate_rootfs) ;
	}
}
